AUTOSAR XML (schema 4-0-3)
package /ComponentTypes
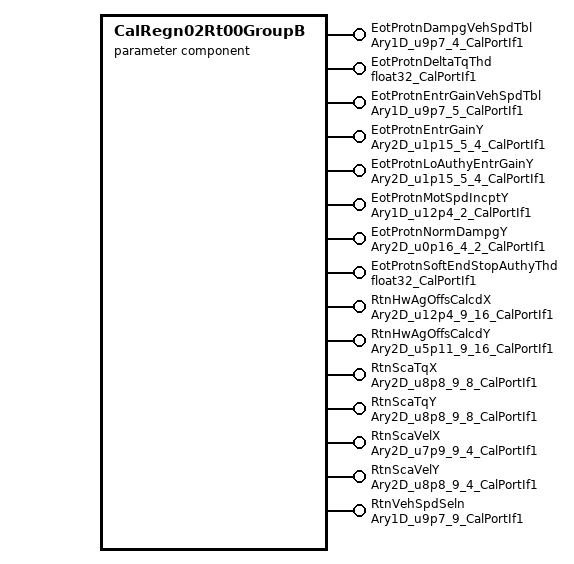
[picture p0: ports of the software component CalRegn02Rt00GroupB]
  parameter sw component type CalRegn02Rt00GroupB
    15 x provide port:
      EotProtnDampgVehSpdTbl: parameter-provide-com-spec{init-value=[0, 640, 1280, 2560], parameter=Ary1D}, provided-interface=Ary1D_u9p7_4_CalPortIf1
      EotProtnDeltaTqThd: parameter-provide-com-spec{init-value=0, parameter=Val}, provided-interface=float32_CalPortIf1
      EotProtnEntrGainVehSpdTbl: parameter-provide-com-spec{init-value=[0, 640, 1280, 1920, 2560], parameter=Ary1D}, provided-interface=Ary1D_u9p7_5_CalPortIf1
      EotProtnEntrGainY: parameter-provide-com-spec{init-value=5 x [0, 10813, 21627, 32768], parameter=Ary2D}, provided-interface=Ary2D_u1p15_5_4_CalPortIf1
      EotProtnLoAuthyEntrGainY: parameter-provide-com-spec{init-value=5 x [0, 9830, 22938, 32768], parameter=Ary2D}, provided-interface=Ary2D_u1p15_5_4_CalPortIf1
      EotProtnMotSpdIncptY: parameter-provide-com-spec{init-value=[10400, 10400], parameter=Ary1D}, provided-interface=Ary1D_u12p4_2_CalPortIf1
      EotProtnNormDampgY: parameter-provide-com-spec{init-value=[[0, 262], [0, 262], [0, 262], [0, 262]], parameter=Ary2D}, provided-interface=Ary2D_u0p16_4_2_CalPortIf1
      EotProtnSoftEndStopAuthyThd: parameter-provide-com-spec{init-value=0.9, parameter=Val}, provided-interface=float32_CalPortIf1
      RtnHwAgOffsCalcdX: parameter-provide-com-spec{init-value=9 x [0, 8, 16, 80, 160, 320, 480, 720, 960, 1440, 1920, 2880, 4320, 5760, 7200, 8640], parameter=Ary2D}, provided-interface=Ary2D_u12p4_9_16_CalPortIf1
      RtnHwAgOffsCalcdY: parameter-provide-com-spec{init-value=9 x 16 x 0, parameter=Ary2D}, provided-interface=Ary2D_u5p11_9_16_CalPortIf1
      RtnScaTqX: parameter-provide-com-spec{init-value=9 x [0, 128, 256, 512, 768, 1024, 1280, 2560], parameter=Ary2D}, provided-interface=Ary2D_u8p8_9_8_CalPortIf1
      RtnScaTqY: parameter-provide-com-spec{init-value=9 x 8 x 256, parameter=Ary2D}, provided-interface=Ary2D_u8p8_9_8_CalPortIf1
      RtnScaVelX: parameter-provide-com-spec{init-value=9 x [0, 20480, 21504, 21504], parameter=Ary2D}, provided-interface=Ary2D_u7p9_9_4_CalPortIf1
      RtnScaVelY: parameter-provide-com-spec{init-value=9 x [256, 256, 256, 256], parameter=Ary2D}, provided-interface=Ary2D_u8p8_9_4_CalPortIf1
      RtnVehSpdSeln: parameter-provide-com-spec{init-value=[0, 384, 896, 1536, 2560, 3840, 5760, 7680, 10240], parameter=Ary1D}, provided-interface=Ary1D_u9p7_9_CalPortIf1
